# SC32F10T_10G register map
File version: 1.0
CPU: CM0+ r0p1, little endian, MPU, no FPU, 4 interrupt priority bits
Registers are 32-bit, access not given, reset 0x0 unless marked. A register's access mark holds for its fields unless they carry their own. Offsets are from the block's base; lines under a group give offsets from that group; [hi:lo] are bit positions; {n}, {i} and the like mark numbered series; 'fields as' and 'values as' point back to an identical list; <NAME> marks a mode.

## Memory map
0x40000330 WDT size 0x14
0x400003C0 IAP size 0x10
0x400003F8 OPT size 0x8 — OPT peripheral (OPT_TypeDef)
0x40002000 CRC size 0x10
0x40003000 RCCAHB size 0x8 — RCCAHB peripheral (RCCAHB_TypeDef)
0x4000300C RCC size 0x24
0x40010800 DMA0 size 0x14
0x40010840 DMA1 size 0x14
0x40010880 DMA2 size 0x14
0x400108C0 DMA3 size 0x14
0x40011000 GPIOA size 0x64 — GPIOA peripheral (GPIO_TypeDef)
0x40011000 GPIOA_BIT size 0x24 — GPIOA_BIT peripheral (GPIO_BIT_TypeDef)
0x40011000 GPIOB_BIT size 0x24 — GPIOB_BIT peripheral (GPIO_BIT_TypeDef)
0x40011000 GPIOC_BIT size 0x24 — GPIOC_BIT peripheral (GPIO_BIT_TypeDef)
0x40011100 GPIOB size 0x64 — GPIOB peripheral (GPIO_TypeDef)
0x40011200 GPIOC size 0x64 — GPIOC peripheral (GPIO_TypeDef)
0x40011300 EXTI size 0xE4 — EXTI peripheral (EXTI_TypeDef)
0x40020000 RCCAPB0 size 0x8 — RCCAPB0 peripheral (RCCAPB0_TypeDef)
0x40020020 UART0 size 0x14
0x40020040 SPI0 size 0x14
0x40020060 TWI0 size 0x14
0x40020080 UART1 size 0x14
0x40020100 TIM0 size 0x1C
0x40020140 TIM1 size 0x1C
0x40020180 TIM2 size 0x1C
0x400201C0 TIM3 size 0x1C
0x40020200 PWM0 size 0x34
0x40021000 RCCAPB1 size 0x8 — RCCAPB1 peripheral (RCCAPB1_TypeDef)
0x40021020 UART2 size 0x14
0x40021040 SPI1 size 0x14
0x40021060 TWI1 size 0x14
0x40021100 TIM4 size 0x1C
0x40021140 TIM5 size 0x1C
0x40021180 TIM6 size 0x1C
0x400211C0 TIM7 size 0x1C
0x40022000 RCCAPB2 size 0x8 — RCCAPB2 peripheral (RCCAPB2_TypeDef)
0x40022020 UART3 size 0x14
0x40022100 BTM size 0x8
0x40022110 ADC size 0x10
0x40022130 CMP size 0x8
0x40022140 FPGA size 0x4 — FPGA peripheral (PGA_TypeDef)
0x40022200 TK size 0x20 — TK peripheral (TK_TypeDef)
0x40022280 LCD_LED size 0x14 — LCD_LED peripheral (LCD_LED_TypeDef)
0x40022300 PWM1 size 0x34 — PWM0

## Interrupts
4 RCC — < RCC shut down Interrupts
6 BTM — < BTM Interrupts
7 UART0_2 (UART{n} (n=0..2)) — < UART0 and UART2 Interrupts
8 UART1_3 (UART{n} (n=1..3)) — < UART1 and UART3 Interrupts
9 SPI0 — < SPI0 Interrupts
10 SPI1 — < SPI1 Interrupts
11 DMA0 — < DMA0 Interrupts
12 DMA1 — < DMA1 Interrupts
13 DMA2 — < DMA2 Interrupts
14 DMA3 — < DMA3 Interrupts
21 PWM0 — < PWM0 Interrupt
22 PWM1 — < PWM1 Interrupt
23 TWI0 — < TWI0 Interrupt
24 TWI1 — < TWI1 Interrupt
29 ADC — < ADC Interrupt
30 CMP — < CMP Interrupt
31 TK — < TouchKey Interrupt

## RCC
Base 0x4000300C
0x00 RCC_KEY — RCC保护寄存器
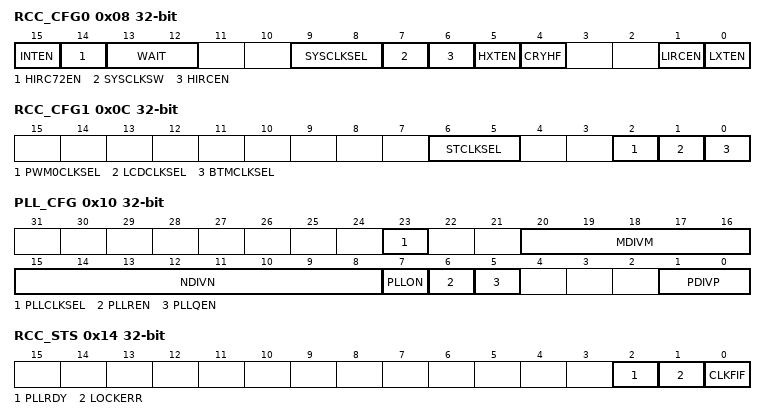
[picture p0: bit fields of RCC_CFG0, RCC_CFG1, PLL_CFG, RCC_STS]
0x08 RCC_CFG0 rw — 系统时钟源选择寄存器
  [15] INTEN — 中断请求 CPU的使能控制位 0：禁止中断请求 1：使能中断请求
  [14] HIRC72EN
  [13:12] WAIT
  [9:8] SYSCLKSEL — 系统时钟源选择位00：系统时钟源来自LIRC01：系统时钟源来自HXT10：系统时钟源来自PLLR11：系统时钟源来自LXT注意：上电默认的系统时钟源为HIRC，用户可在上电后的正常操作阶段，通过软件方式切换时钟源。切换前务必确保所选时钟源已处于稳定的工作状态；系统时钟源无论选择切换至哪一种，都必须先将系统时钟源切换至HIRC，再切换至目标时钟源。
  [7] SYSCLKSW — 系统时钟源切换位，使能后系统时钟源从HIRC切换至SYSCLKSEL所选的时钟：0：系统时钟源为HIRC1：系统时钟源为SYSCLKSEL设置项对此位改写后，必须内部电路切换成功才会更新改写的值，否则读到的一直是改写前的状态。用户可以通过读取此位的方式判断时钟源是否已切换成功。复位/唤醒后此位将自动清零，即复位/唤醒后由HIRC提供系统时钟。注意：上电默认的系统时钟源为HIRC，用户可在上电后的正
  [6] HIRCEN — 内建高频32MHz振荡器HIRC使能位0：禁止1：使能当SYSCLKSW = 0，选择HIRC作为系统时钟时，此位不可写入。复位/唤醒后此位将由硬件置1，即复位/唤醒后由HIRC提供系统时钟。
  [5] HXTEN — 外接高频晶振HXT使能位0：禁止1：使能复位/唤醒后此位将自动清零。
  [4] CRYHF — 外接高频晶振HXT振荡频率范围选择位0：外接晶振振荡频率<12M1：外接晶振振荡频率≥12M
  [1] LIRCEN — 内建低频32kHz振荡器LIRC使能位0：禁止1：使能
  [0] LXTEN — 外接低频晶振LXT使能位0：禁止1：使能
0x0C RCC_CFG1 rw — 外设时钟源选择寄存器
  [6:5] STCLKSEL — SysTick时钟源选择位000：时钟源来自HCLK/8001：时钟源来自HIRC/2010：时钟源来自HXT/2011：时钟源来自LIRC100：时钟源来自LXT注意：用户配置时注意，如果 SysTick时钟源不是来自HCLK，SysTick时钟源频率必须小于或等于fHCLK/2。
  [2] PWM0CLKSEL
  [1] LCDCLKSEL — LCD时钟源选择位0：时钟源来自LIRC1：时钟源来自LXT对此位改写后，必须等待内部电路切换成功才会更新改写的值，否则读到的一直是改写前的状态。用户可以通过读取此位的方式判断时钟源是否已切换成功。
  [0] BTMCLKSEL — BTM时钟源选择位0：时钟源来自LIRC1：时钟源来自LXT对此位改写后，必须等待内部电路切换成功才会更新改写的值，否则读到的一直是改写前的状态。用户可以通过读取此位的方式判断时钟源是否已切换成功。
0x10 PLL_CFG rw — PLL配置寄存器
  [23] PLLCLKSEL — PLL时钟源选择位1：PLL时钟源来自外部高速晶振 HXT，PLL输入时钟的频率fPLL_IN = fHXT0：PLL时钟源来自内部高速震荡时钟 HIRC，PLL输入时钟的频率fPLL_IN = fHIRC注意：只有在禁止 PLL 时才能写入此位域。
  [20:16] MDIVM — PLL时钟源预分频有效值：0x01~0x1F注意：用户需自行配置保证PLL输入频率分至2MHz。
  [15:8] NDIVN — PLL倍频系数2 <= N <=192 0x00、0x01及大于192的值：无效计算公式：fPLLR = [ ( fPLL_IN / DIVM ) * DIVN ] / 2 ^ ( DIVP +1 )注意：用户需自行配置保证倍频后频率保持在200MHz ~ 400MHz之间, 之后用户需自行配置DIVP分频保证输出频率PLLR不高于64MHz， PLLR可作为系统时钟源。
  [7] PLLON — PLL使能位0：PLL关闭1：PLL使能当进入停止、待机或关断模式时由硬件清零。注意：如果 PLL 时钟用作系统时钟，则此位不可为0。
  [6] PLLREN — PLLRCLK 时钟输出使能位0：禁止1：使能选择 PLL 的 PLLRCLK 输出作为系统时钟时，此位不可写入。
  [5] PLLQEN
  [1:0] PDIVP
0x14 RCC_STS access per field — 时钟状态寄存器
  [2] PLLRDY ro — PLL 时钟就绪标志位该位只读，由硬件置 1，用于指示 PLL 已锁定。0：PLL 未锁定1：PLL 已锁定
  [1] LOCKERR rw
  [0] CLKFIF rw
0x1C SYST_CALIB — SysTick校准参数寄存器
0x20 NMI_CFG — NMI中断配置寄存器
